# STM32F103xE register map
File version: 1.0
Registers are 32-bit, read-write, reset 0x0 unless marked. A register's access mark holds for its fields unless they carry their own. Offsets are from the block's base; [hi:lo] are bit positions; lines under a group give offsets from that group.

## ADC12_COMMON
Base 0x40012400; alternate view of ADC1
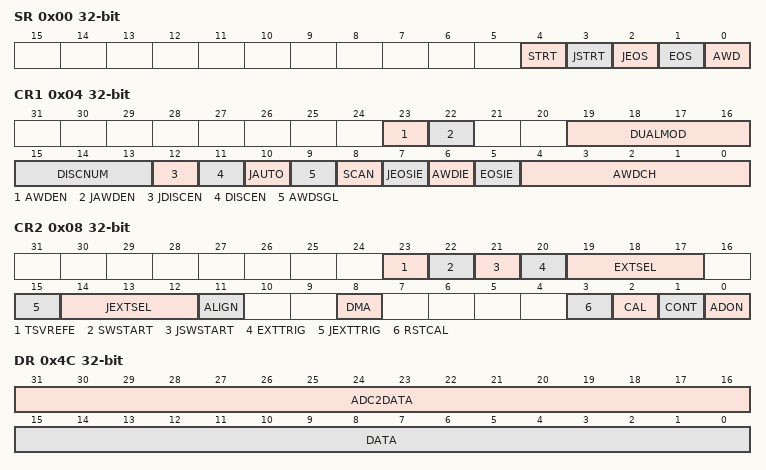
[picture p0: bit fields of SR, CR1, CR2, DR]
0x00 SR — ADC status register, used for ADC multimode (bits common to several ADC instances)
  [4] STRT — ADC group regular conversion start flag
  [3] JSTRT — ADC group injected conversion start flag
  [2] JEOS — ADC group injected end of sequence conversions flag
  [1] EOS — ADC group regular end of sequence conversions flag
  [0] AWD — ADC analog watchdog 1 flag
0x04 CR1 — ADC control register 1, used for ADC multimode (bits common to several ADC instances)
  [23] AWDEN — ADC analog watchdog 1 enable on scope ADC group regular
  [22] JAWDEN — ADC analog watchdog 1 enable on scope ADC group injected
  [19:16] DUALMOD — ADC multimode mode selection
    0=INDEPENDENT (ADC dual mode disabled (ADC independent mode)); 6=DUAL_REG_SIMULT (ADC dual mode enabled: group regular simultaneous); 7=DUAL_REG_INTERL_FAST (ADC dual mode enabled: Combined group regular interleaved fast (delay between ADC sampling phases: 7 ADC clock cycles) (equivalent to multimode sampling delay set to "LL_ADC_MULTI_TWOSMP_DELAY_7CYCLES" on other STM32 devices))); 8=DUAL_REG_INTERL_SLOW (ADC dual mode enabled: Combined group regular interleaved slow (delay between ADC sampling phases: 14 ADC clock cycles) (equivalent to multimode sampling delay set to "LL_ADC_MULTI_TWOSMP_DELAY_14CYCLES" on other STM32 devices))); 5=DUAL_INJ_SIMULT (ADC dual mode enabled: group injected simultaneous slow (delay between ADC sampling phases: 14 ADC clock cycles) (equivalent to multimode sampling delay set to "LL_ADC_MULTI_TWOSMP_DELAY_14CYCLES" on other STM32 devices))); 9=DUAL_INJ_ALTERN (ADC dual mode enabled: group injected alternate trigger. Works only with external triggers (not internal SW start)); 1=DUAL_REG_SIM_INJ_SIM (ADC dual mode enabled: Combined group regular simultaneous + group injected simultaneous); 2=DUAL_REG_SIM_INJ_ALT (ADC dual mode enabled: Combined group regular simultaneous + group injected alternate trigger); 3=DUAL_REG_INTFAST_INJ_SIM (ADC dual mode enabled: Combined group regular interleaved fast (delay between ADC sampling phases: 7 ADC clock cycles) + group injected simultaneous); 4=DUAL_REG_INTSLOW_INJ_SIM (ADC dual mode enabled: Combined group regular interleaved slow (delay between ADC sampling phases: 14 ADC clock cycles) + group injected simultaneous)
  [15:13] DISCNUM — ADC group regular sequencer discontinuous number of ranks
  [12] JDISCEN — ADC group injected sequencer discontinuous mode
    0=DISABLE (ADC group injected sequencer discontinuous mode disable); 1=DISCONT_1RANK (ADC group injected sequencer discontinuous mode enable with sequence interruption every rank)
  [11] DISCEN — ADC group regular sequencer discontinuous mode
  [10] JAUTO — ADC group injected automatic trigger mode
    0=INDEPENDENT (ADC group injected conversion trigger independent. Setting mandatory if ADC group injected injected trigger source is set to an external trigger.); 1=FROM_GRP_REGULAR (ADC group injected conversion trigger from ADC group regular. Setting compliant only with group injected trigger source set to SW start, without any further action on ADC group injected conversion start or stop: in this case, ADC group injected is controlled only from ADC group regular.)
  [9] AWDSGL — ADC analog watchdog 1 monitoring a single channel or all channels
  [8] SCAN — ADC scan mode
    0=DISABLE (ADC conversion is performed in unitary conversion mode (one channel converted, that defined in rank 1). Configuration of both groups regular and injected sequencers (sequence length, ...) is discarded: equivalent to length of 1 rank.); 1=ENABLE (ADC conversions are performed in sequence conversions mode, according to configuration of both groups regular and injected sequencers (sequence length, ...).)
  [7] JEOSIE — ADC group injected end of sequence conversions interrupt
  [6] AWDIE — ADC analog watchdog 1 interrupt
  [5] EOSIE — ADC group regular end of sequence conversions interrupt
  [4:0] AWDCH — ADC analog watchdog 1 monitored channel selection
0x08 CR2 — ADC control register 2, used for ADC multimode (bits common to several ADC instances)
  [23] TSVREFE — ADC internal path to VrefInt and temperature sensor enable
    0=NONE (ADC measurement paths all disabled); 1=VREFINT (ADC measurement path to internal channel VrefInt)
  [22] SWSTART — ADC group regular conversion start
  [21] JSWSTART — ADC group injected conversion start
  [20] EXTTRIG — ADC group regular external trigger enable
  [19:17] EXTSEL — ADC group regular external trigger source
    7=SOFTWARE (ADC group regular conversion trigger internal: SW start.); 2=EXT_TIM1_CH3 (ADC group regular conversion trigger from external IP: TIM1 channel 3 event (capture compare: input capture or output capture). Trigger edge set to rising edge (default setting).); 0=EXT_TIM1_CH1 (ADC group regular conversion trigger from external IP: TIM1 channel 1 event (capture compare: input capture or output capture). Trigger edge set to rising edge (default setting).); 1=EXT_TIM1_CH2 (ADC group regular conversion trigger from external IP: TIM1 channel 2 event (capture compare: input capture or output capture). Trigger edge set to rising edge (default setting).); 3=EXT_TIM2_CH2 (ADC group regular conversion trigger from external IP: TIM2 channel 2 event (capture compare: input capture or output capture). Trigger edge set to rising edge (default setting).); 4=EXT_TIM3_TRGO (ADC group regular conversion trigger from external IP: TIM3 TRGO. Trigger edge set to rising edge (default setting).); 5=EXT_TIM4_CH4 (ADC group regular conversion trigger from external IP: TIM4 channel 4 event (capture compare: input capture or output capture). Trigger edge set to rising edge (default setting).); 6=EXT_EXTI_LINE11 (ADC group regular conversion trigger from external IP: external interrupt line 11. Trigger edge set to rising edge (default setting).)
  [15] JEXTTRIG — ADC group injected external trigger enable
  [14:12] JEXTSEL — ADC group injected external trigger source
    7=SOFTWARE (ADC group injected conversion trigger internal: SW start.); 0=EXT_TIM1_TRGO (ADC group injected conversion trigger from external IP: TIM1 TRGO. Trigger edge set to rising edge (default setting).); 1=EXT_TIM1_CH4 (ADC group injected conversion trigger from external IP: TIM1 channel 4 event (capture compare: input capture or output capture). Trigger edge set to rising edge (default setting).); 2=EXT_TIM2_TRGO (ADC group injected conversion trigger from external IP: TIM2 TRGO. Trigger edge set to rising edge (default setting).); 3=EXT_TIM2_CH1 (ADC group injected conversion trigger from external IP: TIM2 channel 1 event (capture compare: input capture or output capture). Trigger edge set to rising edge (default setting).); 4=EXT_TIM3_CH4 (ADC group injected conversion trigger from external IP: TIM3 channel 4 event (capture compare: input capture or output capture). Trigger edge set to rising edge (default setting).); 5=EXT_TIM4_TRGO (ADC group injected conversion trigger from external IP: TIM4 TRGO. Trigger edge set to rising edge (default setting).); 6=EXT_EXTI_LINE15 (ADC group injected conversion trigger from external IP: external interrupt line 15. Trigger edge set to rising edge (default setting).)
  [11] ALIGN — ADC data alignment
    0=RIGHT (ADC conversion data alignment: right aligned (alignment on data register LSB bit 0)); 1=LEFT (ADC conversion data alignment: left aligned (alignment on data register MSB bit 15))
  [8] DMA — ADC DMA transfer enable
    0=NONE (ADC conversions are not transferred by DMA); 1=UNLIMITED (ADC conversion data are transferred by DMA, in unlimited mode: DMA transfer requests are unlimited, whatever number of DMA data transferred (number of ADC conversions). This ADC mode is intended to be used with DMA mode circular.)
  [3] RSTCAL — ADC calibration reset
  [2] CAL — ADC calibration start
  [1] CONT — ADC group regular continuous conversion mode
    0=SINGLE (ADC conversions are performed in single mode: one conversion per trigger); 1=CONTINUOUS (ADC conversions are performed in continuous mode: after the first trigger, following conversions launched successively automatically)
  [0] ADON — ADC enable
0x4C DR — ADC data register, used for ADC multimode (bits common to several ADC instances)
  [31:16] ADC2DATA — ADC group regular conversion data for ADC slave, in multimode
  [15:0] DATA — ADC group regular conversion data
